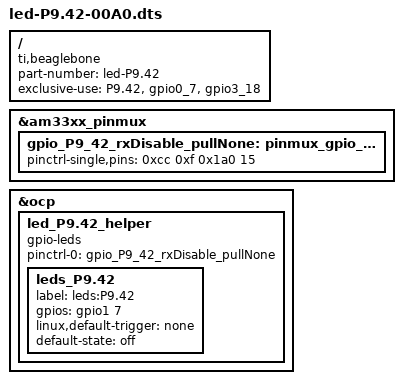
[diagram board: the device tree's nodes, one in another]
/*
* Easy gpio mux control of "P9.42" ("gpio0_7", "gpio3_18")
*/
/dts-v1/;
/plugin/;

/ {
	compatible = "ti,beaglebone", "ti,beaglebone-black";

	/* identification */
	part-number = "led-P9.42";
	/* version = "00A0"; */

	/* state the resources this cape uses */
	exclusive-use =
		/* the pin header uses */
		"P9.42",

		/* the hardware IP uses */
		"gpio0_7", "gpio3_18";
	
	
	/* rxDisable_pullNone state */
	fragment@0 {
		target = <&am33xx_pinmux>;
		__overlay__ {
			gpio_P9_42_rxDisable_pullNone: pinmux_gpio_P9.42_rxDisable_pullNone {
				pinctrl-single,pins = <
					0xcc 0xf	0x1a0 15
				>;
			};
		};
	};

	fragment@1 {
		target = <&ocp>;
		__overlay__ {
			led_P9.42_helper {
				compatible = "gpio-leds";
				pinctrl-names = "default";
				pinctrl-0 = <&gpio_P9_42_rxDisable_pullNone>;
				
				leds_P9.42 {
					label = "leds:P9.42";
					gpios = <&gpio1 7 0>;
					linux,default-trigger = "none";
					default-state = "off";
				};
			};
			
		};
	};

};
